# ESP32-C5 register map
Vendor: ESPRESSIF SYSTEMS (SHANGHAI) CO., LTD.; Series: ESP32 C-Series; File version: 1
CPU: RV32IMAC r0p0, little endian, no MPU, no FPU, 0 interrupt priority bits
Address unit: 32 bits
Registers are 32-bit, read-write, reset 0x0 unless marked. A register's access mark holds for its fields unless they carry their own. Offsets are from the block's base; [hi:lo] are bit positions; {n}, {i} and the like mark numbered series.

## TWAI0 — Two-Wire Automotive Interface
Base 0x6000B000
Same registers: TWAI1 0x6000D000
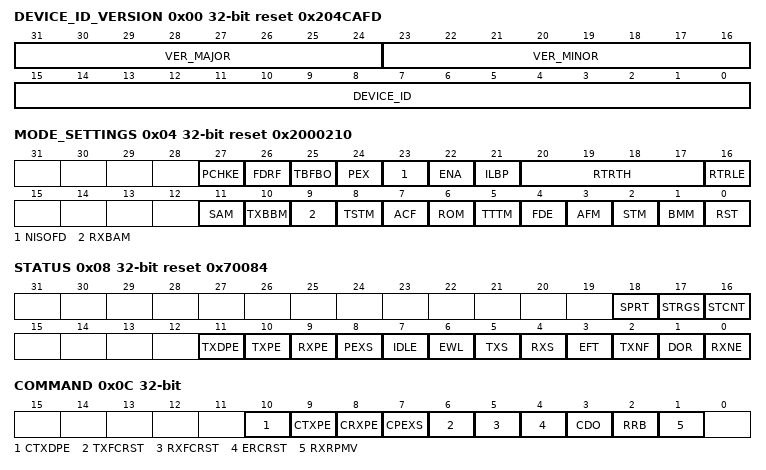
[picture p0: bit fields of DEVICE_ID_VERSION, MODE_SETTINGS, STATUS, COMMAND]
0x00 DEVICE_ID_VERSION ro reset 0x204CAFD — TWAI FD device id status register
  [31:24] VER_MAJOR — TWAI FD IP version
  [23:16] VER_MINOR — TWAI FD IP version
  [15:0] DEVICE_ID — Represents whether CAN IP function is mapped correctly on its base address.
0x04 MODE_SETTINGS access per field reset 0x2000210 — TWAI FD mode setting register
  [27] PCHKE rw — Enable Parity checks in TXT Buffers and RX Buffer.
  [26] FDRF rw — Frame filters drop Remote frames. 0b0 - DROP_RF_DISABLED - Frame filters accept RTR frames. 0b1 - DROP_RF_ENABLED - Frame filters drop RTR frames.
  [25] TBFBO rw — All TXT buffers shall go to "TX failed" state when CTU CAN FD becomes bus-off. 0b0 - TXTBUF_FAILED_BUS_OFF_DISABLED - TXT Buffers dont go to "TX failed" state when CTU CAN FD becomes bus-off. 0b1 - TXTBUF_FAILED_BUS_OFF_ENABLED - TXT Buffers go to "TX failed" state when CTU CAN FD becomes bus-off.
  [24] PEX rw — Protocol exception handling. When this bit is set, CTU CAN FD will start integration upon detection of protocol exception. This should be modified only when SETTINGS[ENA] = ’0’. 0b0 - PROTOCOL_EXCEPTION_DISABLED - Protocol exception handling is disabled. 0b1 - PROTOCOL_EXCEPTION_ENABLED - Protocol exception handling is enabled.
  [23] NISOFD rw — Non ISO FD. When this bit is set, CTU CAN FD is compliant to NON-ISO CAN FD specification (no stuff count field). This bit should be modified only when SETTINGS[ENA]=0. 0b0 - ISO_FD - The CAN Controller conforms to ISO CAN FD specification. 0b1 - NON_ISO_FD - The CAN Controller conforms to NON ISO CAN FD specification. CANFD 1.0
  [22] ENA rw — Main enable bit of CTU CAN FD. When enabled, CTU CAN FD communicates on CAN bus. When disabled, it is bus-off and does not take part of CAN bus communication. 0b0 - CTU_CAN_DISABLED - The CAN Core is disabled. 0b1 - CTU_CAN_ENABLED - The CAN Core is enabled.
  [21] ILBP rw — Internal Loop Back mode. When enabled, CTU CAN FD receives any frame it transmitts. 0b0 - INT_LOOP_DISABLED - Internal loop-back is disabled. 0b1 - INT_LOOP_ENABLED - Internal loop-back is enabled.
  [20:17] RTRTH rw — Retransmitt Limit Threshold. Maximal amount of retransmission attempts when SETTINGS[RTRLE] is en- Abled.
  [16] RTRLE rw — Retransmitt Limit Enable. If enabled, CTU CAN FD only attempts to retransmitt each frame up to RTR_TH times. 0b0 - RTRLE_DISABLED - Retransmitt limit is disabled. 0b1 - RTRLE_ENABLED - Retransmitt limit is enabled.
  [11] SAM rw — Self-acknowledge mode.\\ 0b0 - SAM_DISABLE - Do not send dominant ACK bit when CTU CAN FD sends Acknowledge bit.\\ 0b1 - SAM_ENABLE - Send dominant ACK bit when CTU CAN FD transmits CAN frame.\\
  [10] TXBBM rw — TXT Buffer Backup mode\\ 0b0 - TXBBM_DISABLED - TXT Buffer Backup mode disabled\\ 0b1 - TXBBM_ENABLED - TXT Buffer Backup mode enabled\\
  [9] RXBAM rw — RX Buffer automatic mode. 0b0 - RXBAM_DISABLED - 0b1 - RXBAM_ENABLED -
  [8] TSTM rw — Test Mode. In test mode several registers have special features. Reffer to description of Test mode for further Details.
  [7] ACF rw — Acknowledge Forbidden Mode. When enabled, acknowledge is not sent even if received CRC matches the calculated one. 0b0 - ACF_DISABLED - Acknowledge forbidden mode disabled. 0b1 - ACF_ENABLED - Acknowledge forbidden mode enabled.
  [6] ROM rw — Restricted operation mode. 0b0 - ROM_DISABLED - Restricted operation mode is disabled. 0b1 - ROM_ENABLED - Restricted operation mode is enabled.
  [5] TTTM rw — Time triggered transmission mode. 0b0 - TTTM_DISABLED - 0b1 - TTTM_ENABLED -
  [4] FDE rw — Flexible data rate enable. When flexible data rate is enabled CTU CAN FD recognizes CAN FD frames (FDF bit = 1). 0b0 - FDE_DISABLE - Flexible data-rate support disabled. 0b1 - FDE_ENABLE - Flexible data-rate support enabled.
  [3] AFM rw — Acceptance Filters Mode. If enabled, only RX frames which pass Frame filters are stored in RX buffer. If disabled, every received frame is stored to RX buffer. This bit has meaning only if there is at least one filter available. Otherwise, this bit is reserved. 0b0 - AFM_DISABLED - Acceptance filter mode disabled 0b1 - AFM_ENABLED - Acceptance filter mode enabled
  [2] STM rw — Self Test Mode. In this mode transmitted frame is considered valid even if dominant acknowledge was not received. 0b0 - STM_DISABLED - Self test mode disabled. 0b1 - STM_ENABLED - Self test mode enabled.
  [1] BMM rw — Bus monitoring mode. In this mode CTU CAN FD only receives frames and sends only recessive bits on CAN bus. When a dominant bit is sent, it is re-routed internally so that bus value is not changed. When this mode is enabled, CTU CAN FD will not transmit any frame from TXT Buffers, 0b0 - BMM_DISABLED - Bus monitoring mode disabled. 0b1 - BMM_ENABLED - Bus monitoring mode enabled.
  [0] RST wo — Soft reset. Writing logic 1 resets CTU CAN FD. After writing logic 1, logic 0 does not need to be written, this bit is automatically cleared. 0: invalid 1: reset.
0x08 STATUS ro reset 0x70084 — TWAI FD status register
  [18] SPRT — Support of Parity protection on each word of TXT Buffer RAM and RX Buffer RAM.
  [17] STRGS — Support of Test Registers for memory testability. When this bit is 1, Test Registers are present.
  [16] STCNT — Support of Traffic counters. When this bit is 1, Traffic counters are present.
  [11] TXDPE — TXT Buffer double parity error. Set in TXT Buffer Backup mode when parity error is detected in "backup" TXT Buffer.
  [10] TXPE — TXT Buffers Parity Error flag. Set When Parity Error is detected in a TXT Buffer during transmission from this Buffer.
  [9] RXPE — Set when parity error is detected during read of CAN frame from RX Buffer via RX_DATA register.
  [8] PEXS — Protocol exception status (flag). Set when Protocol exception occurs. Cleared by writing COMMAND[CPEXS]=1.
  [7] IDLE — Bus is idle (no frame is being transmitted/received) or CTU CAN FD is bus-off. 0: active 1: not active
  [6] EWL — TX Error counter (TEC) or RX Error counter (REC) is equal to, or higher than Error warning limit (EWL). 0: not reached 1: reached
  [5] TXS — CTU CAN FD is transmitter of CAN Frame. 0: not transmitting 1: transmitting
  [4] RXS — CTU CAN FD is receiver of CAN Frame. 0: not receiving 1: receiving
  [3] EFT — Error frame is being transmitted at the moment. 0: not being transmitted 1: being transmitted
  [2] TXNF — TXT buffers status. This bit is set if at least one TXT buffer is in "Empty" state. 0: not full 1: full
  [1] DOR — Data Overrun flag. This bit is set when frame was dropped due to lack of space in RX buffer. This bit can be cleared by COMMAND[RRB]. 0: not overrun 1: overrun
  [0] RXNE — RX buffer not empty. This bit is 1 when least one frame is stored in RX buffer. 0: empty 1: not empty
0x0C COMMAND wo — TWAI FD command register
  [10] CTXDPE — Clear STATUS[TXDPE] flag.
  [9] CTXPE — Clear STATUS[TXPE] flag.
  [8] CRXPE — Clear STATUS[RXPE] flag.
  [7] CPEXS — Clear Protocol exception status (STATUS[PEXS]).
  [6] TXFCRST — Clear TX bus traffic counter (TX_COUNTER register).
  [5] RXFCRST — Clear RX bus traffic counter (RX_COUNTER register).
  [4] ERCRST — Error Counters Reset. When unit is bus off, issuing this command will request erasing TEC, REC counters after 128 consecutive ocurrences of 11 recessive bits. Upon completion, TEC and REC are erased and fault confinement State is set to error-active. When unit is not bus-off, or when unit is bus-off due to being disabled (SETTINGS[ENA] = ’0’), this command has no effect.
  [3] CDO — Clear Data Overrun flag in RX buffer. 0: invalid 1: clear
  [2] RRB — Release RX Buffer. This command flushes RX buffer and resets its memory pointers. 0: invalid 1: delete
  [1] RXRPMV — RX Buffer read pointer move.
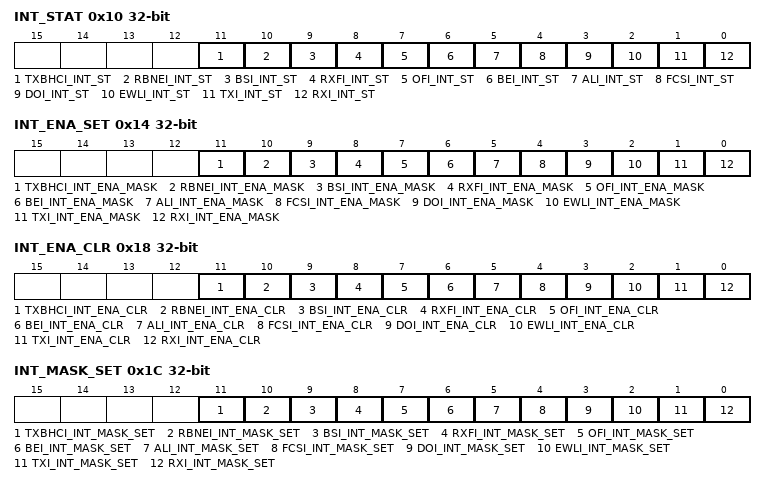
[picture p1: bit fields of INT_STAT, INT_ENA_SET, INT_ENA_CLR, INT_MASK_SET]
0x10 INT_STAT — TWAI FD command register
  [11] TXBHCI_INT_ST — The masked interrupt status of TWAIFD_TXBHCI_INT. TXT buffer HW command interrupt. Anytime TXT buffer receives HW command from CAN Core which changes TXT buffer state to "TX OK", "Error" or "Aborted", this interrupt will be generated.
  [10] RBNEI_INT_ST — The masked interrupt status of TWAIFD_RBNEI_INT. RX buffer not empty interrupt. Clearing this interrupt and not reading out content of RX Buffer via RX_DATA will re-activate the interrupt.
  [9] BSI_INT_ST — The masked interrupt status of TWAIFD_BSI_INT. Bit rate shifted interrupt.
  [8] RXFI_INT_ST — The masked interrupt status of TWAIFD_RXFI_INT. RX buffer full interrupt.
  [7] OFI_INT_ST — The masked interrupt status of TWAIFD_OFI_INT. Overload frame interrupt.
  [6] BEI_INT_ST — The masked interrupt status of TWAIFD_BEI_INT. Bus error interrupt.
  [5] ALI_INT_ST — The masked interrupt status of TWAIFD_ALI_INT. Arbitration lost interrupt.
  [4] FCSI_INT_ST — The masked interrupt status of TWAIFD_FCSI_INT. Fault confinement state changed interrupt. Interrupt is set when node turns error-passive (from error-active), bus-off (from error-passive) or error-active (from bus-off after reintegration or from error-passive).
  [3] DOI_INT_ST — The masked interrupt status of TWAIFD_DOI_INT. Data overrun interrupt. Before this Interrupt is cleared , STATUS[DOR] must be cleared to avoid setting of this Interrupt again.
  [2] EWLI_INT_ST — The masked interrupt status of TWAIFD_EWLI_INT. Error warning limit interrupt. When both TEC and REC are lower than EWL and one of the becomes equal to or higher than EWL, or when both TEC and REC become less than EWL, this interrupt is generated. When Interrupt is cleared and REC, or TEC is still equal to or higher than EWL, Interrupt is not generated again.
  [1] TXI_INT_ST — The masked interrupt status of TWAIFD_TXI_INT. Frame transmitted interrupt.
  [0] RXI_INT_ST — The masked interrupt status of TWAIFD_RXI_INT. Frame received interrupt.
0x14 INT_ENA_SET — TWAI FD interrupt enable register
  [11] TXBHCI_INT_ENA_MASK — Write 1 to enable TWAIFD_TXBHCI_INT.
  [10] RBNEI_INT_ENA_MASK — Write 1 to enable TWAIFD_RBNEI_INT.
  [9] BSI_INT_ENA_MASK — Write 1 to enable TWAIFD_BSI_INT.
  [8] RXFI_INT_ENA_MASK — Write 1 to enable TWAIFD_RXFI_INT.
  [7] OFI_INT_ENA_MASK — Write 1 to enable TWAIFD_OFI_INT.
  [6] BEI_INT_ENA_MASK — Write 1 to enable TWAIFD_BEI_INT.
  [5] ALI_INT_ENA_MASK — Write 1 to enable TWAIFD_ALI_INT.
  [4] FCSI_INT_ENA_MASK — Write 1 to enable TWAIFD_FCSI_INT.
  [3] DOI_INT_ENA_MASK — Write 1 to enable TWAIFD_DOI_INT.
  [2] EWLI_INT_ENA_MASK — Write 1 to enable TWAIFD_EWLI_INT.
  [1] TXI_INT_ENA_MASK — Write 1 to enable TWAIFD_TXI_INT.
  [0] RXI_INT_ENA_MASK — Write 1 to enable TWAIFD_RXI_INT.
0x18 INT_ENA_CLR wo — TWAI FD interrupt enable clear register
  [11] TXBHCI_INT_ENA_CLR — Write 1 to clear TWAIFD_TXBHCI_INT_ENA .
  [10] RBNEI_INT_ENA_CLR — Write 1 to clear TWAIFD_RBNEI_INT_ENA .
  [9] BSI_INT_ENA_CLR — Write 1 to clear TWAIFD_BSI_INT_ENA .
  [8] RXFI_INT_ENA_CLR — Write 1 to clear TWAIFD_RXFI_INT_ENA .
  [7] OFI_INT_ENA_CLR — Write 1 to clear TWAIFD_OFI_INT_ENA .
  [6] BEI_INT_ENA_CLR — Write 1 to clear TWAIFD_BEI_INT_ENA .
  [5] ALI_INT_ENA_CLR — Write 1 to clear TWAIFD_ALI_INT_ENA .
  [4] FCSI_INT_ENA_CLR — Write 1 to clear TWAIFD_FCSI_INT_ENA .
  [3] DOI_INT_ENA_CLR — Write 1 to clear TWAIFD_DOI_INT_ENA .
  [2] EWLI_INT_ENA_CLR — Write 1 to clear TWAIFD_EWLI_INT_ENA .
  [1] TXI_INT_ENA_CLR — Write 1 to clear TWAIFD_TXI_INT_ENA .
  [0] RXI_INT_ENA_CLR — Write 1 to clear TWAIFD_RXI_INT_ENA .
0x1C INT_MASK_SET — TWAI FD interrupt mask register
  [11] TXBHCI_INT_MASK_SET — Write 1 to mask TWAIFD_TXBHCI_INT.
  [10] RBNEI_INT_MASK_SET — Write 1 to mask TWAIFD_RBNEI_INT.
  [9] BSI_INT_MASK_SET — Write 1 to mask TWAIFD_BSI_INT.
  [8] RXFI_INT_MASK_SET — Write 1 to mask TWAIFD_RXFI_INT.
  [7] OFI_INT_MASK_SET — Write 1 to mask TWAIFD_OFI_INT.
  [6] BEI_INT_MASK_SET — Write 1 to mask TWAIFD_BEI_INT.
  [5] ALI_INT_MASK_SET — Write 1 to mask TWAIFD_ALI_INT.
  [4] FCSI_INT_MASK_SET — Write 1 to mask TWAIFD_FCSI_INT.
  [3] DOI_INT_MASK_SET — Write 1 to mask TWAIFD_DOI_INT.
  [2] EWLI_INT_MASK_SET — Write 1 to mask TWAIFD_EWLI_INT.
  [1] TXI_INT_MASK_SET — Write 1 to mask TWAIFD_TXI_INT.
  [0] RXI_INT_MASK_SET — Write 1 to mask TWAIFD_RXI_INT.
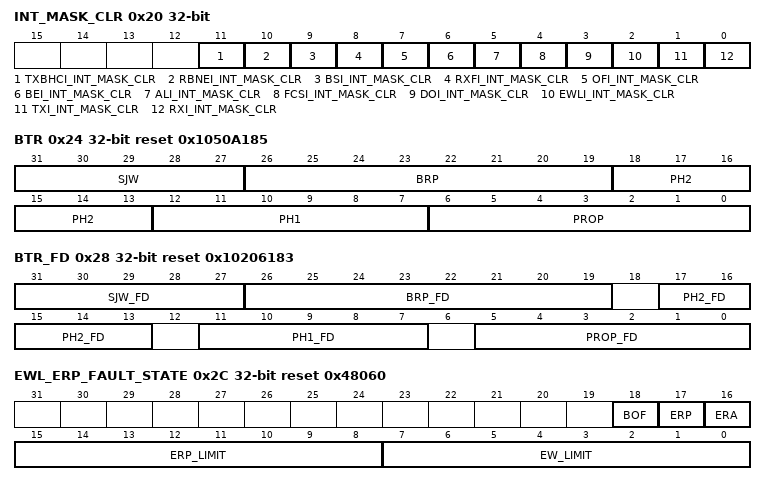
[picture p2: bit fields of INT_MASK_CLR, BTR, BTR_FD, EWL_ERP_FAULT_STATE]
0x20 INT_MASK_CLR wo — TWAI FD interrupt mask clear register
  [11] TXBHCI_INT_MASK_CLR — Write 1 to clear TWAIFD_TXBHCI_INT_MASK_CLR .
  [10] RBNEI_INT_MASK_CLR — Write 1 to clear TWAIFD_RBNEI_INT_MASK_CLR .
  [9] BSI_INT_MASK_CLR — Write 1 to clear TWAIFD_BSI_INT_MASK_CLR .
  [8] RXFI_INT_MASK_CLR — Write 1 to clear TWAIFD_RXFI_INT_MASK_CLR .
  [7] OFI_INT_MASK_CLR — Write 1 to clear TWAIFD_OFI_INT_MASK_CLR .
  [6] BEI_INT_MASK_CLR — Write 1 to clear TWAIFD_BEI_INT_MASK_CLR .
  [5] ALI_INT_MASK_CLR — Write 1 to clear TWAIFD_ALI_INT_MASK_CLR .
  [4] FCSI_INT_MASK_CLR — Write 1 to clear TWAIFD_FCSI_INT_MASK_CLR .
  [3] DOI_INT_MASK_CLR — Write 1 to clear TWAIFD_DOI_INT_MASK_CLR .
  [2] EWLI_INT_MASK_CLR — Write 1 to clear TWAIFD_EWLI_INT_MASK_CLR .
  [1] TXI_INT_MASK_CLR — Write 1 to clear TWAIFD_TXI_INT_MASK_CLR .
  [0] RXI_INT_MASK_CLR — Write 1 to clear TWAIFD_RXI_INT_MASK_CLR .
0x24 BTR reset 0x1050A185 — TWAI FD bit-timing register
  [31:27] SJW — Represents the synchronization jump width in nominal bit time. Measurement unit: time quanta
  [26:19] BRP — Configures the baud-rate prescaler of nominal bit rate. Measurement unit: cycle of core clock.
  [18:13] PH2 — Configures the phase 2 segment of nominal bit rate. Measurement unit: time quanta
  [12:7] PH1 — Configures the phase 1 segment of nominal bit rate. Measurement unit: time quanta
  [6:0] PROP — Configures the propagation segment of nominal bit rate. Measurement unit: time quanta
0x28 BTR_FD reset 0x10206183 — TWAI FD bit-timing of FD register
  [31:27] SJW_FD — Represents the synchronization jump width in data bit time. Measurement unit: time quanta
  [26:19] BRP_FD — Configures the baud-rate prescaler of data bit rate. Measurement unit: cycle of core clock.
  [17:13] PH2_FD — Configures the phase 2 segment of data bit rate. Measurement unit: time quanta
  [11:7] PH1_FD — Configures the phase 1 segment of data bit rate. Measurement unit: time quanta
  [5:0] PROP_FD — Configures the propagation segment of data bit rate. Measurement unit: time quanta
0x2C EWL_ERP_FAULT_STATE access per field reset 0x48060 — TWAI FD error threshold and status register
  [18] BOF ro — Represents the fault state of bus off.
  [17] ERP ro — Represents the fault state of error passive.
  [16] ERA ro — Represents the fault state of error active.
  [15:8] ERP_LIMIT rw — Error Passive Limit. When one of error counters (REC/TEC) exceeds this value, Fault confinement state changes to error-passive.
  [7:0] EW_LIMIT rw — Error warning limit. If error warning limit is reached interrupt can be generated. Error warning limit indicates heavily disturbed bus.
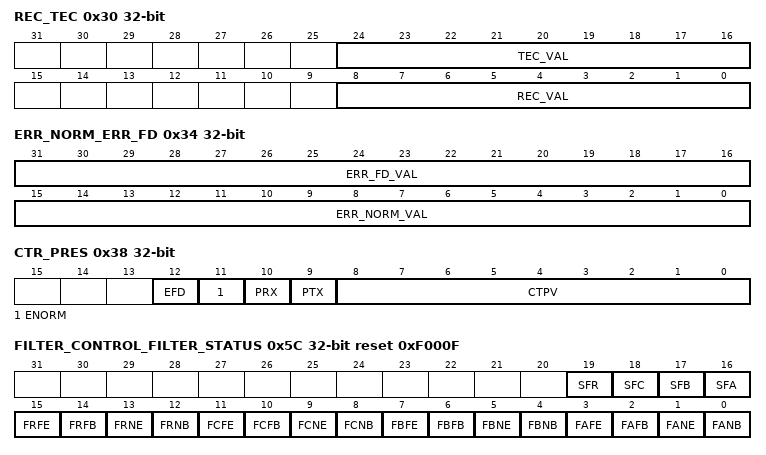
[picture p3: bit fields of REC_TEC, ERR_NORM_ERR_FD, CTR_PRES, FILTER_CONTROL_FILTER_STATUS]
0x30 REC_TEC ro — TWAI FD error counters status register
  [24:16] TEC_VAL — Represents the transmitter error counter value.
  [8:0] REC_VAL — Represents the receiver error counter value.
0x34 ERR_NORM_ERR_FD ro — TWAI FD special error counters status register
  [31:16] ERR_FD_VAL — Represents the number of error in the data bit time.
  [15:0] ERR_NORM_VAL — Represents the number of error in the nominal bit time.
0x38 CTR_PRES wo — TWAI FD error counters pre-define configuration register
  [12] EFD — Configures whether or not to erase the error counter of data bit time. 0: invalid 1: erase
  [11] ENORM — Configures whether or not to erase the error counter of nominal bit time. 0: invalid 1: erase
  [10] PRX — Configures whether or not to set the transmitter error counter into the value of pre-defined value. 0: invalid 1: set
  [9] PTX — Configures whether or not to set the receiver error counter into the value of pre-defined value. 0: invalid 1: set
  [8:0] CTPV — Configures the pre-defined value to set the error counter.
0x3C FILTER_A_MASK — TWAI FD filter A mask value register
  [28:0] BIT_MASK_A_VAL — Filter A mask. The identifier format is the same as in IDENTIFIER_W of TXT buffer or RX buffer. If filter A is not present, writes to this register have no effect and read will return all zeroes.
0x40 FILTER_A_VAL — TWAI FD filter A bit value register
  [28:0] BIT_VAL_A_VAL — Filter A value. The identifier format is the same as in IDENTIFIER_W of TXT buffer or RX buffer. If filter A is not present, writes to this register have no effect and read will return all zeroes.
0x44 FILTER_B_MASK — TWAI FD filter B mask value register
  [28:0] BIT_MASK_B_VAL — Filter B mask. The identifier format is the same as in IDENTIFIER_W of TXT buffer or RX buffer. If filter A is not present, writes to this register have no effect and read will return all zeroes.
0x48 FILTER_B_VAL — TWAI FD filter B bit value register
  [28:0] BIT_VAL_B_VAL — Filter B value. The identifier format is the same as in IDENTIFIER_W of TXT buffer or RX buffer. If filter A is not present, writes to this register have no effect and read will return all zeroes.
0x4C FILTER_C_MASK — TWAI FD filter C mask value register
  [28:0] BIT_MASK_C_VAL — Filter C mask. The identifier format is the same as in IDENTIFIER_W of TXT buffer or RX buffer. If filter A is not present, writes to this register have no effect and read will return all zeroes.
0x50 FILTER_C_VAL — TWAI FD filter C bit value register
  [28:0] BIT_VAL_C_VAL — Filter C value. The identifier format is the same as in IDENTIFIER_W of TXT buffer or RX buffer. If filter A is not present, writes to this register have no effect and read will return all zeroes.
0x54 FILTER_RAN_LOW — TWAI FD filter range low value register
  [28:0] BIT_RAN_LOW_VAL — Filter Range Low threshold. The identifier format is the same as in IDENTIFIER_W of TXT buffer or RX buffer. If Range filter is not supported, writes to this register have no effect and read will return all Zeroes.
0x58 FILTER_RAN_HIGH — TWAI FD filter range high value register
  [28:0] BIT_RAN_HIGH_VAL — Range filter High threshold. The identifier format is the same as in IDENTIFIER_W of TXT buffer or RX buffer. If Range filter is not supported, writes to this register have no effect and read will return all Zeroes.
0x5C FILTER_CONTROL_FILTER_STATUS access per field reset 0xF000F — TWAI FD filter control register
  [19] SFR ro — Logic 1 when Range Filter is available. Otherwise logic 0.
  [18] SFC ro — Logic 1 when Filter C is available. Otherwise logic 0.
  [17] SFB ro — Logic 1 when Filter B is available. Otherwise logic 0.
  [16] SFA ro — Logic 1 when Filter A is available. Otherwise logic 0.
  [15] FRFE rw — CAN FD Extended Frame is accepted by Range filter.
  [14] FRFB rw — CAN FD Basic Frame is accepted by Range filter.
  [13] FRNE rw — CAN Extended Frame is accepted by Range filter.
  [12] FRNB rw — CAN Basic Frame is accepted by Range filter.
  [11] FCFE rw — CAN FD Extended Frame is accepted by filter C.
  [10] FCFB rw — CAN FD Basic Frame is accepted by filter C.
  [9] FCNE rw — CAN Extended Frame is accepted by Filter C.
  [8] FCNB rw — CAN Basic Frame is accepted by filter C.
  [7] FBFE rw — CAN FD Extended Frame is accepted by filter B.
  [6] FBFB rw — CAN FD Basic Frame is accepted by filter B.
  [5] FBNE rw — CAN Extended Frame is accepted by Filter B.
  [4] FBNB rw — CAN Basic Frame is accepted by filter B.
  [3] FAFE rw — CAN FD Extended Frame is accepted by filter A.
  [2] FAFB rw — CAN FD Basic Frame is accepted by filter A.
  [1] FANE rw — CAN Extended Frame is accepted by Filter A.
  [0] FANB rw — CAN Basic Frame is accepted by filter A.
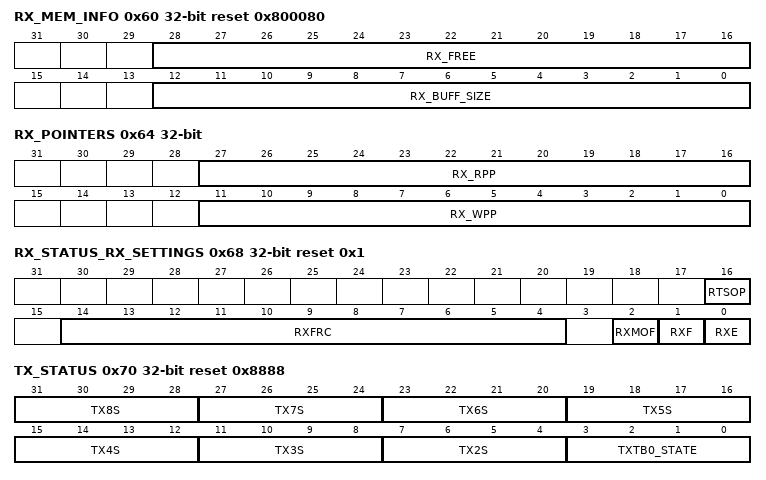
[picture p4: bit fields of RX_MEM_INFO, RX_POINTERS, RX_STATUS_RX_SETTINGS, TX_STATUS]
0x60 RX_MEM_INFO ro reset 0x800080 — TWAI FD rx memory information register
  [28:16] RX_FREE — Number of free 32 bit words in RX buffer.
  [12:0] RX_BUFF_SIZE — Size of RX buffer in 32-bit words.
0x64 RX_POINTERS ro — TWAI FD rx memory pointer information register
  [27:16] RX_RPP — Read pointer position in RX buffer. Upon read of received frame read pointer is updated.
  [11:0] RX_WPP — Write pointer position in RX buffer. Upon store of received frame write pointer is updated.
0x68 RX_STATUS_RX_SETTINGS access per field reset 0x1 — TWAI FD rx status & setting register
  [16] RTSOP rw — Receive buffer timestamp option. This register should be modified only when SETTINGS[ENA]=0. 0b0 - RTS_END - Timestamp of received frame in RX FIFO is captured in last bit of EOF field. 0b1 - RTS_BEG - Timestamp of received frame in RX FIFO is captured in SOF field.
  [14:4] RXFRC ro — RX buffer frame count. Number of CAN frames stored in RX buffer.
  [2] RXMOF ro — Represents the number of received frame in RX buffer. RX Buffer middle of frame. When RXMOF = 1, next read from RX_DATA register will return other than first word (FRAME_FORMAT_W) of CAN frame.
  [1] RXF ro — Represents whether or not the RX buffer is full. RX buffer is full, all memory words of RX buffer are occupied. 0: not full 1: full
  [0] RXE ro — Represents whether or not the RX buffer is empty. RX buffer is empty. There is no CAN Frame stored in it. 0: not empty 1: empty
0x6C RX_DATA ro — TWAI FD received data register
  [31:0] RX_DATA — RX buffer data at read pointer position in FIFO. By reading from this register, read pointer is auto- matically increased, as long as there is next data word stored in RX buffer. First stored word in the buffer is FRAME_FORMAT_W, next IDENTIFIER_W etc. This register shall be read by 32 bit access.
0x70 TX_STATUS ro reset 0x8888 — TWAI FD TX buffer status register
  [4n-1:4n-4] TX{n}S (n=2..8) — Status of TXT buffer {n}. Bit field meaning is analogous to TX1S.
  [3:0] TXTB0_STATE — Status of TXT buffer 1. 0b0000 - TXT_NOT_EXIST - TXT buffer does not exist in the core (applies only to TXT buffers 3-8, when CTU CAN FD was synthesized with less than 8 TXT buffers). 0b0001 - TXT_RDY - TXT buffer is in "Ready" state, it is waiting for CTU CAN FD to start transmission from it. 0b0010 - TXT_TRAN - TXT buffer is in "TX in progress" state. CTU CAN FD is transmitting frame. 0b0011 - TXT_ABTP - TXT buffer is in "Abort in progress" state. 0b0100 - TXT_TOK - TXT buffer is in "TX OK" state. 0b0110 - TXT_ERR - TXT buffer is in "Failed" state. 0b0111 - TXT_ABT - TXT buffer is in "Aborted" state. 0b1000 - TXT_ETY - TXT buffer is in "Empty" state.
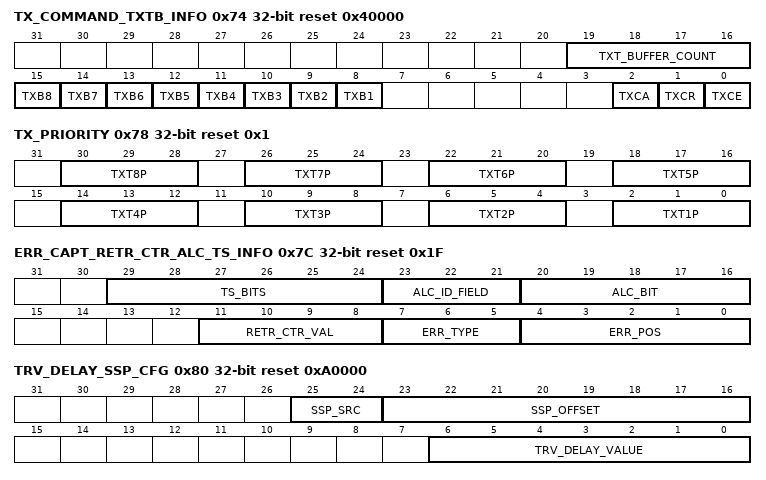
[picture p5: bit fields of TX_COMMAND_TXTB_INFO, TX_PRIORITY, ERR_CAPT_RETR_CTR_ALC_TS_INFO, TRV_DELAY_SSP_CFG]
0x74 TX_COMMAND_TXTB_INFO access per field reset 0x40000 — TWAI FD TXT buffer command & information register
  [19:16] TXT_BUFFER_COUNT ro — Number of TXT buffers present in CTU CAN FD. Lowest buffer is always 1. Highest buffer is at index equal to number of present buffers.
  [n+7] TXB{n} wo (n=3..8) — Command is issued to TXT Buffer {n}. If number of TXT Buffers is less than {n}, this field is reserved and has no Function.
  [9] TXB2 wo — Command is issued to TXT Buffer 2.
  [8] TXB1 wo — Command is issued to TXT Buffer 1.
  [2] TXCA wo — Issues "set abort" command.
  [1] TXCR wo — Issues "set ready" command.
  [0] TXCE wo — Issues "set empty" command.
0x78 TX_PRIORITY reset 0x1 — TWAI FD TXT buffer command & information register
  [4n-2:4n-4] TXT{n}P (n=3..8) — Priority of TXT buffer {n}. If number of TXT Buffers is less than {n}, this field is reserved and has no function.
  [6:4] TXT2P — Priority of TXT buffer 2.
  [2:0] TXT1P — Priority of TXT buffer 1.
0x7C ERR_CAPT_RETR_CTR_ALC_TS_INFO ro reset 0x1F — TWAI FD error capture & retransmit counter & arbitration lost & timestamp integration information register
  [29:24] TS_BITS — Number of active bits of CTU CAN FD time-base minus 1 (0x3F = 64 bit time-base).
  [23:21] ALC_ID_FIELD — Part of CAN Identifier in which arbitration was lost. 0b000 - ALC_RSVD - Unit did not loose arbitration since last reset. 0b001 - ALC_BASE_ID - Arbitration was lost during base identifier. 0b010 - ALC_SRR_RTR - Arbitration was lost during first bit after base identifier (SRR of Extended Frame, RTR bit of CAN 2.0 Base Frame) 0b011 - ALC_IDE - Arbitration was lost during IDE bit. 0b100 - ALC_EXTENSION - Arbitration was lost during Identifier extension. 0b101 - ALC_RTR - Arbitration was lost during RTR bit after Identifier extension!
  [20:16] ALC_BIT — Arbitration lost capture bit position. If ALC_ID_FIELD = ALC_BASE_ID then bit index of BASE identifier in which arbitration was lost is given as: 11 - ALC_VAL. If ALC_ID_FIELD = ALC_EXTENSION then bit index of EXTENDED identifier in which arbitration was lost is given as: 18 - ALC_VAL. For other values of ALC_ID_FIELD, this value is undefined.
  [11:8] RETR_CTR_VAL — Current value of retransmitt counter.
  [7:5] ERR_TYPE — Type of last error. 0b000 - ERC_BIT_ERR - Bit Error 0b001 - ERC_CRC_ERR - CRC Error 0b010 - ERC_FRM_ERR - Form Error 0b011 - ERC_ACK_ERR - Acknowledge Error 0b100 - ERC_STUF_ERR - Stuff Error
  [4:0] ERR_POS — 0b00000 - ERC_POS_SOF - Error in Start of Frame 0b00001 - ERC_POS_ARB - Error in Arbitration Filed 0b00010 - ERC_POS_CTRL - Error in Control field 0b00011 - ERC_POS_DATA - Error in Data Field 0b00100 - ERC_POS_CRC - Error in CRC Field 0b00101 - ERC_POS_ACK - Error in CRC delimiter, ACK field or ACK delimiter 0b00110 - ERC_POS_EOF - Error in End of frame field 0b00111 - ERC_POS_ERR - Error during Error frame 0b01000 - ERC_POS_OVRL - Error in Overload frame 0b11111 - ERC_POS_OTHER - Other position of error
0x80 TRV_DELAY_SSP_CFG access per field reset 0xA0000 — TWAI FD transmit delay & secondary sample point configuration register
  [25:24] SSP_SRC rw — Source of Secondary sampling point. 0b00 - SSP_SRC_MEAS_N_OFFSET - SSP position = TRV_DELAY (Measured Transmitter delay) + SSP_OFFSET. 0b01 - SSP_SRC_NO_SSP - SSP is not used. Transmitter uses regular Sampling Point during data bit rate. 0b10 - SSP_SRC_OFFSET - SSP position = SSP_OFFSET. Measured Transmitter delay value is ignored.
  [23:16] SSP_OFFSET rw — Secondary sampling point offset. Value is given as multiple of minimal Time quanta.
  [6:0] TRV_DELAY_VALUE ro — Measured Transmitter delay in multiple of minimal Time quanta.
0x84 RX_FR_CTR ro — TWAI FD received frame counter register
  [31:0] VAL — Number of received frames by CTU CAN FD.
0x88 TX_FR_CTR ro — TWAI FD transmitted frame counter register
  [31:0] TX_CTR_VAL — Number of transmitted frames by CTU CAN FD.
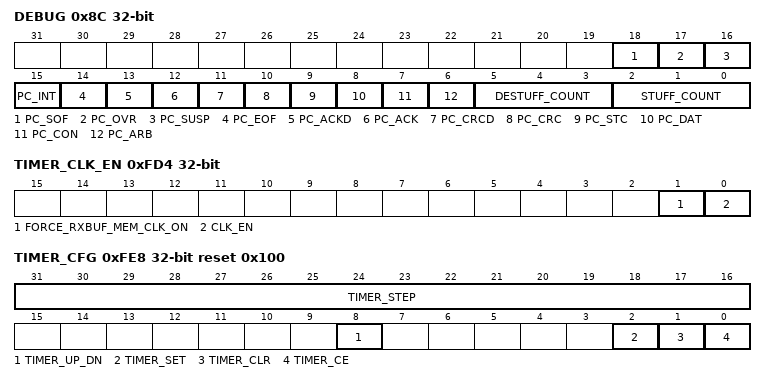
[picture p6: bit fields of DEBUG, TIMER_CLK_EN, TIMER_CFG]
0x8C DEBUG ro — TWAI FD debug register
  [18] PC_SOF — Protocol control state machine is in Start of frame field.
  [17] PC_OVR — Protocol control state machine is in Overload field.
  [16] PC_SUSP — Protocol control state machine is in Suspend transmission field.
  [15] PC_INT — Protocol control state machine is in Intermission field.
  [14] PC_EOF — Protocol control state machine is in End of file field.
  [13] PC_ACKD — Protocol control state machine is in ACK Delimiter field.
  [12] PC_ACK — Protocol control state machine is in ACK field.
  [11] PC_CRCD — Protocol control state machine is in CRC Delimiter field.
  [10] PC_CRC — Protocol control state machine is in CRC field.
  [9] PC_STC — Protocol control state machine is in Stuff Count field.
  [8] PC_DAT — Protocol control state machine is in Data field.
  [7] PC_CON — Protocol control state machine is in Control field.
  [6] PC_ARB — Protocol control state machine is in Arbitration field.
  [5:3] DESTUFF_COUNT — Actual de-stuff count modulo 8 as defined in ISO FD protocol. De-Stuff count is erased in the beginning of the frame and increased by one with each de-stuffed bit until Stuff count field in ISO FD Frame. Then it stays fixed until beginning of next frame. In non-ISO FD or normal CAN de-stuff bits are counted until the end of the frame. Note that this field is NOT grey encoded as defined in ISO FD standard. De-stuff count is calculated in both. Transceiver as well as receiver.
  [2:0] STUFF_COUNT — Actual stuff count modulo 8 as definned in ISO FD protocol. Stuff count is erased in the beginning of CAN frame and increased by one with each stuff bit until Stuff count field in ISO FD frame. Then it stays fixed until the beginning of next frame. In non-ISO FD or normal CAN stuff bits are counted until the end of a frame. Note that this field is NOT gray encoded as defined in ISO FD standard. Stuff count is calculated only as long as controller is transceiving on the bus. During the reception this value remains fixed!
0x90 YOLO ro reset 0xDEADBEEF — TWAI FD transmitted frame counter register
  [31:0] VAL — What else could be in this register??
0x94 TIMESTAMP_LOW ro — TWAI FD transmitted frame counter register
  [31:0] TIMESTAMP_LOW — Bits 31:0 of time base.
0x98 TIMESTAMP_HIGH ro — TWAI FD transmitted frame counter register
  [31:0] TIMESTAMP_HIGH — Bits 63:32 of time base.
{0x100+4i} TXTB1_DATA{i} (i=0..19) wo — TX buffer 1 frame memory word
  [31:0] DATA — Frame buffer word
{0x200+4i} TXTB2_DATA{i} (i=0..19) wo — TX buffer 2 frame memory word
  [31:0] DATA — Frame buffer word
{0x300+4i} TXTB3_DATA{i} (i=0..19) wo — TX buffer 3 frame memory word
  [31:0] DATA — Frame buffer word
{0x400+4i} TXTB4_DATA{i} (i=0..19) wo — TX buffer 4 frame memory word
  [31:0] DATA — Frame buffer word
0xFD4 TIMER_CLK_EN — TWAIFD timer clock force enable register.
  [1] FORCE_RXBUF_MEM_CLK_ON — Set this bit to force enable TWAIFD RX buffer ram clock signal.
  [0] CLK_EN — Set this bit to force enable TWAIFD register configuration clock signal.
0xFD8 TIMER_INT_RAW ro — TWAIFD raw interrupt register.
  [0] TIMER_OVERFLOW_INT_RAW — The raw bit signal for read_done interrupt.
0xFDC TIMER_INT_ST ro — TWAIFD interrupt status register.
  [0] TIMER_OVERFLOW_INT_ST — The status signal for read_done interrupt.
0xFE0 TIMER_INT_ENA — TWAIFD interrupt enable register.
  [0] TIMER_OVERFLOW_INT_ENA — The enable signal for read_done interrupt.
0xFE4 TIMER_INT_CLR wo — TWAIFD interrupt clear register.
  [0] TIMER_OVERFLOW_INT_CLR — The clear signal for read_done interrupt.
0xFE8 TIMER_CFG access per field reset 0x100 — TWAI FD timer configure register.
  [31:16] TIMER_STEP rw — TWAI FD timer count step register, step=reg_timer_step+1
  [8] TIMER_UP_DN rw — TWAI FD timer up/down count register. 1b0: Count-down 1b1: Count-up
  [2] TIMER_SET wo — TWAI FD timer set register. 1b0: Not enable 1b1: Enable to set value to ld_val.
  [1] TIMER_CLR wo — TWAI FD timer clear register. 1b0: Not enable 1b1: Enable to clear value
  [0] TIMER_CE rw — TWAI FD timer enable register. 1b0: Not enable 1b1: Enable timer
0xFEC TIMER_LD_VAL_L — TWAI FD timer pre-load value low register.
  [31:0] TIMER_LD_VAL_L — TWAI FD timer count pre-load value register, low part.
0xFF0 TIMER_LD_VAL_H — TWAI FD timer pre-load value high register.
  [31:0] TIMER_LD_VAL_H — TWAI FD timer pre-load value register, high part. If timestamp valid bit-width less than 33, this field is ignored.
0xFF4 TIMER_CT_VAL_L reset 0xFFFFFFFF — TWAI FD timer count-to value low register.
  [31:0] TIMER_CT_VAL_L — TWAI FD timer count-to value register, low part.
0xFF8 TIMER_CT_VAL_H reset 0xFFFFFFFF — TWAI FD timer count-to value high register.
  [31:0] TIMER_CT_VAL_H — TWAI FD timer count-to value register, high part. If timestamp valid bit-width less than 33, this field is ignored.
0xFFC DATE_VER reset 0x2312150 — TWAI FD date version
  [31:0] DATE_VER — TWAI FD version
